# QN908XC register map
Vendor: nxp.com; File version: 1.0
CPU: CM4 r0p1, little endian, no MPU, no FPU, 0x3 interrupt priority bits, 0x0 interrupts
Registers are 32-bit, read-write, reset 0x0 unless marked. A register's access mark holds for its fields unless they carry their own. Offsets are from the block's base; [hi:lo] are bit positions.

## CALIB
Base 0x4000F000
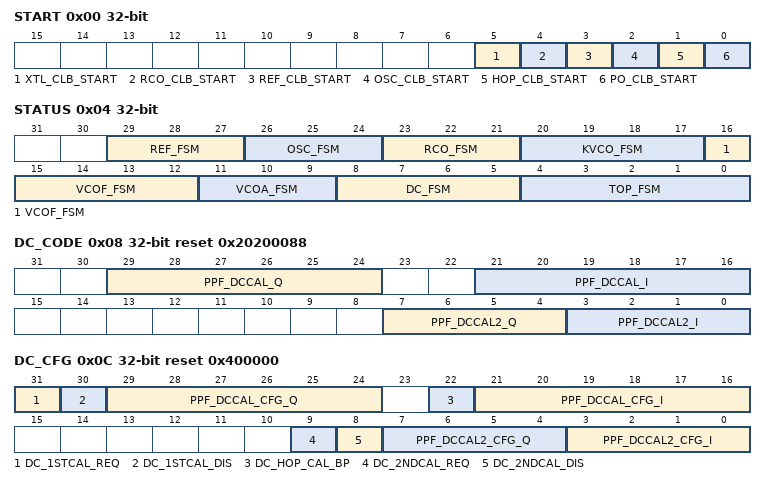
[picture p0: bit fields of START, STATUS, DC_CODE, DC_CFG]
0x00 START reset not defined — calibration start register
  [5] XTL_CLB_START wo — XTAL calibration start
  [4] RCO_CLB_START wo — RCO calibration start
  [3] REF_CLB_START wo — REF PLL calibration start
  [2] OSC_CLB_START wo — OSC calibration start
  [1] HOP_CLB_START wo — Frequency hop calibration start
  [0] PO_CLB_START wo — Power on calibration start
0x04 STATUS ro — calibration FSM status register
  [29:27] REF_FSM, [26:24] OSC_FSM, [23:21] RCO_FSM, [20:17] KVCO_FSM, [16:12] VCOF_FSM, [11:9] VCOA_FSM, [8:5] DC_FSM, [4:0] TOP_FSM
0x08 DC_CODE ro reset 0x20200088 — DC code status register
  [29:24] PPF_DCCAL_Q — DC re-calibration q code
  [21:16] PPF_DCCAL_I — DC re-calibration i code
  [7:4] PPF_DCCAL2_Q — Power on DC calibration q code
  [3:0] PPF_DCCAL2_I — Power on DC calibration i code
0x0C DC_CFG reset 0x400000 — DC code configured code register
  [31] DC_1STCAL_REQ — DC hop calibration request
  [30] DC_1STCAL_DIS — DC hop calibration disable
  [29:24] PPF_DCCAL_CFG_Q — DC re-calibration q code configured
  [22] DC_HOP_CAL_BP — DC hop calibration bypass
  [21:16] PPF_DCCAL_CFG_I — DC re-calibration i code configured
  [9] DC_2NDCAL_REQ — DC calibration request
  [8] DC_2NDCAL_DIS — DC calibration disable
  [7:4] PPF_DCCAL2_CFG_Q — Power on DC calibration q code configured
  [3:0] PPF_DCCAL2_CFG_I — Power on DC calibration i code configured
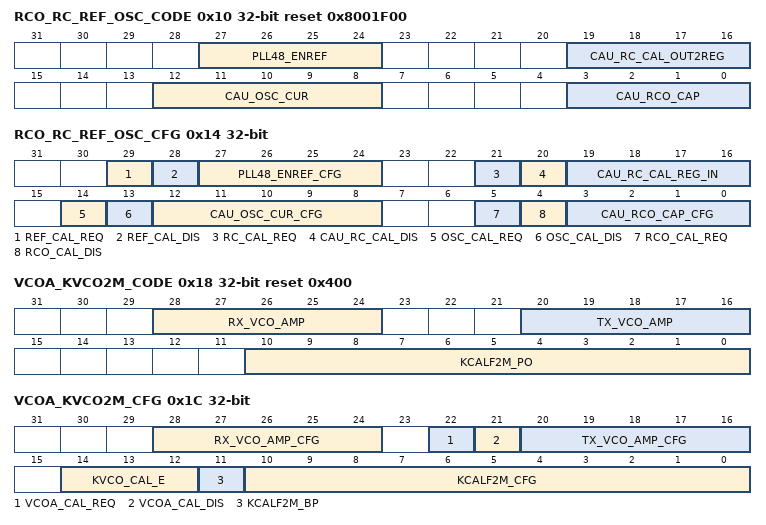
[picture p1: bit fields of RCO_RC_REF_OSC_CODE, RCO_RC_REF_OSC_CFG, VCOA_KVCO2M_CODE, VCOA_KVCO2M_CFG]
0x10 RCO_RC_REF_OSC_CODE ro reset 0x8001F00 — RCO RC PLL48M OSC code status register
  [27:24] PLL48_ENREF — REF calibration output code
  [19:16] CAU_RC_CAL_OUT2REG — RC calibration output code
  [12:8] CAU_OSC_CUR — OSC calibration output code
  [3:0] CAU_RCO_CAP — RCO calibration output code
0x14 RCO_RC_REF_OSC_CFG — RCO RC PLL48M OSC configured code register
  [29] REF_CAL_REQ — REF PLL calibration request
  [28] REF_CAL_DIS — REF PLL calibration disable
  [27:24] PLL48_ENREF_CFG — REF calibration output code configured
  [21] RC_CAL_REQ — RC calibration request
  [20] CAU_RC_CAL_DIS — RC calibration disable
  [19:16] CAU_RC_CAL_REG_IN — RC calibration code to analog
  [14] OSC_CAL_REQ — OSC calibration request
  [13] OSC_CAL_DIS — OSC calibration disable
  [12:8] CAU_OSC_CUR_CFG — OSC calibration output code configured
  [5] RCO_CAL_REQ — RCO calibration request
  [4] RCO_CAL_DIS — RCO calibration disable
  [3:0] CAU_RCO_CAP_CFG — RCO calibration code configured
0x18 VCOA_KVCO2M_CODE ro reset 0x400 — reserved
  [28:24] RX_VCO_AMP — VCO RX amplitude calibration output code
  [20:16] TX_VCO_AMP — VCO TX amplitude calibration output code
  [10:0] KCALF2M_PO — KVCO 2M mode calibration power on code
0x1C VCOA_KVCO2M_CFG — reserved
  [28:24] RX_VCO_AMP_CFG — RX VCO amplitude calibration output code configured
  [22] VCOA_CAL_REQ — VCO amplitude calibration request
  [21] VCOA_CAL_DIS — VCO amplitude calibration disable
  [20:16] TX_VCO_AMP_CFG — TX VCO amplitude calibration output code configured
  [14:12] KVCO_CAL_E
  [11] KCALF2M_BP — bypass KVCO 2M mode power on calibration
  [10:0] KCALF2M_CFG — KVCO 2M mode calibration code configure
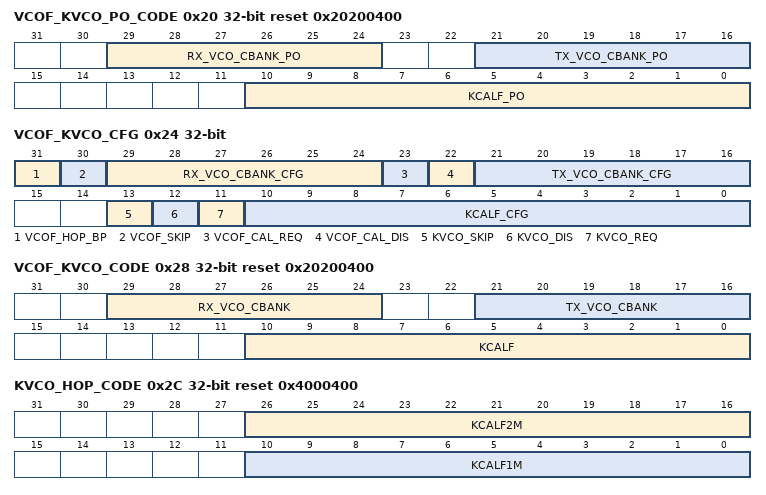
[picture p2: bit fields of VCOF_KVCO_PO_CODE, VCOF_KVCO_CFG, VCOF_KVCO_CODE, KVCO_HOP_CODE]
0x20 VCOF_KVCO_PO_CODE ro reset 0x20200400 — reserved
  [29:24] RX_VCO_CBANK_PO — RX VCO frequency power on calibration output code
  [21:16] TX_VCO_CBANK_PO — TX VCO frequency power on calibration output code
  [10:0] KCALF_PO — KVCO power up calibration result
0x24 VCOF_KVCO_CFG — VCOF hop calibration bypass
  [31] VCOF_HOP_BP — VCOF hop calibration bypass
  [30] VCOF_SKIP — VCOF hop calibration calculation skip
  [29:24] RX_VCO_CBANK_CFG — RX VCO frequency calibration output code configured
  [23] VCOF_CAL_REQ — VCO frequency calibration request
  [22] VCOF_CAL_DIS — VCO frequency calibration disable
  [21:16] TX_VCO_CBANK_CFG — TX VCO frequency calibration output code configured
  [13] KVCO_SKIP — KVCO hop calibration calculation skip
  [12] KVCO_DIS — KVCO calibration disable
  [11] KVCO_REQ — KVCO calibration request
  [10:0] KCALF_CFG — KVCO calibration code configure
0x28 VCOF_KVCO_CODE ro reset 0x20200400 — reserved
  [29:24] RX_VCO_CBANK — RX VCO frequency calibration output code
  [21:16] TX_VCO_CBANK — TX VCO frequency calibration output code
  [10:0] KCALF — KVCO calibration output at carrier frequency
0x2C KVCO_HOP_CODE ro reset 0x4000400 — reserved
  [26:16] KCALF2M — KVCO hop calibration output at carrier frequency in 2M mode
  [10:0] KCALF1M — KVCO hop calibration output at carrier frequency in 1M mode
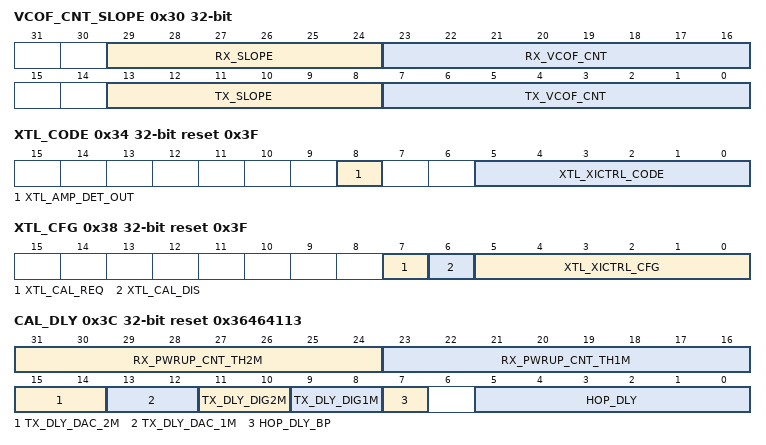
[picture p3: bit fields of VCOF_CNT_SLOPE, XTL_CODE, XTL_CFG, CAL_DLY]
0x30 VCOF_CNT_SLOPE (reset mask 0x1F3F1F3F) — reserved
  [29:24] RX_SLOPE — RX frequency curve slope
  [23:16] RX_VCOF_CNT — RX VCO frequency power up calibration 8us count value
  [13:8] TX_SLOPE — TX frequency curve slope
  [7:0] TX_VCOF_CNT — TX VCO frequency power up calibration 8us count value
0x34 XTL_CODE ro reset 0x3F — Reserved
  [8] XTL_AMP_DET_OUT — crystal comparator output result
  [5:0] XTL_XICTRL_CODE — crystal calibration code
0x38 XTL_CFG reset 0x3F — Reserved
  [7] XTL_CAL_REQ — crystal calibration request
  [6] XTL_CAL_DIS — crystal code disable
  [5:0] XTL_XICTRL_CFG — crystal calibration CFG
0x3C CAL_DLY reset 0x36464113 — hop calibration delay bypass
  [31:24] RX_PWRUP_CNT_TH2M
  [23:16] RX_PWRUP_CNT_TH1M
  [15:14] TX_DLY_DAC_2M
  [13:12] TX_DLY_DAC_1M
  [11:10] TX_DLY_DIG2M
  [9:8] TX_DLY_DIG1M
  [7] HOP_DLY_BP — hop calibration delay bypass
  [5:0] HOP_DLY — hop calibration delay time
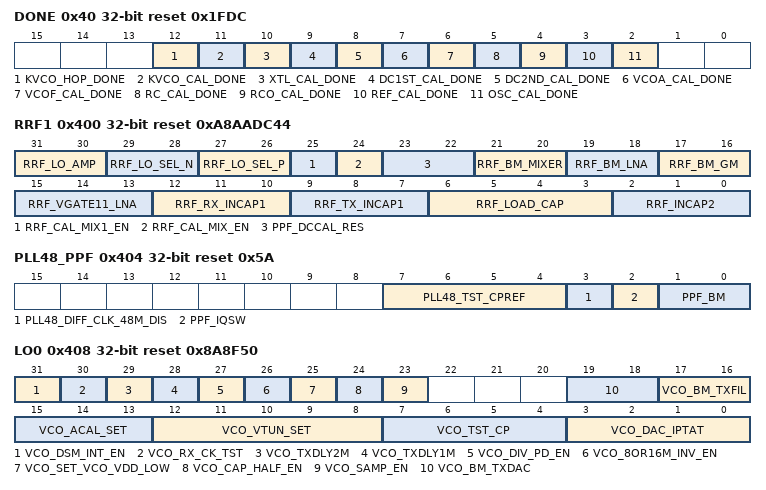
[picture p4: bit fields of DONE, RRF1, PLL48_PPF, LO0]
0x40 DONE ro reset 0x1FDC — Reserved
  [12] KVCO_HOP_DONE — KVCO calibration done
  [11] KVCO_CAL_DONE — KVCO calibration done
  [10] XTL_CAL_DONE — XTL calibration done
  [9] DC1ST_CAL_DONE — DC 1st stage calibration done
  [8] DC2ND_CAL_DONE — DC 2nd stage calibration done
  [7] VCOA_CAL_DONE — VCO amplitude calibration done
  [6] VCOF_CAL_DONE — VCO frequency calibration done
  [5] RC_CAL_DONE — RC calibration done
  [4] RCO_CAL_DONE — RCO calibration done
  [3] REF_CAL_DONE — REF PLL calibration done
  [2] OSC_CAL_DONE — OSC calibration done
0x400 RRF1 reset 0xA8AADC44 — Amplitude of LO buffer for active mixer
  [31:30] RRF_LO_AMP — Amplitude of LO buffer for active mixer
  [29:28] RRF_LO_SEL_N — Dc voltage bias control for the nmos switch of active mixer
  [27:26] RRF_LO_SEL_P — Dc voltage bias control for the pmos switch of active mixer
  [25] RRF_CAL_MIX1_EN
  [24] RRF_CAL_MIX_EN
  [23:22] PPF_DCCAL_RES — Input res selection of ppf for dccal
  [21:20] RRF_BM_MIXER — Mixer current bias
  [19:18] RRF_BM_LNA — LNA bias current control-
  [17:16] RRF_BM_GM — Constant gm current control
  [15:13] RRF_VGATE11_LNA — LNA vrega voltage
  [12:10] RRF_RX_INCAP1 — LNA&PA matching cap bank
  [9:7] RRF_TX_INCAP1 — LNA&PA matching cap bank
  [6:3] RRF_LOAD_CAP — LNA load LC cap bank
  [2:0] RRF_INCAP2 — LNA input LC cap bank
0x404 PLL48_PPF reset 0x5A — reserved
  [7:4] PLL48_TST_CPREF — CP current selecting
  [3] PLL48_DIFF_CLK_48M_DIS
  [2] PPF_IQSW
  [1:0] PPF_BM — Ppf current control-
0x408 LO0 reset 0x8A8F50 — reserved
  [31] VCO_DSM_INT_EN
  [30] VCO_RX_CK_TST
  [29] VCO_TXDLY2M
  [28] VCO_TXDLY1M
  [27] VCO_DIV_PD_EN
  [26] VCO_8OR16M_INV_EN
  [25] VCO_SET_VCO_VDD_LOW
  [24] VCO_CAP_HALF_EN
  [23] VCO_SAMP_EN
  [19:18] VCO_BM_TXDAC — Set the bias current of the TX DAC
  [17:16] VCO_BM_TXFIL — Set the bias current of the TX filter
  [15:13] VCO_ACAL_SET — Set the threshold (differential peak) in VCO amplitude calibration-VTH=0.2+0.05*ACAL_SET
  [12:8] VCO_VTUN_SET — Set VTUNE voltage change in order to properly compensate the VUNE error introduced by charge injection when the PLL loop is broken;VTUNE change introduced by this register is around 50uV*(VTUNE_SET-16)
  [7:4] VCO_TST_CP — LO CP current control-
  [3:0] VCO_DAC_IPTAT — Set the temperature characteristic of TX DAC in order to compensate the modulation gain error of the VCO
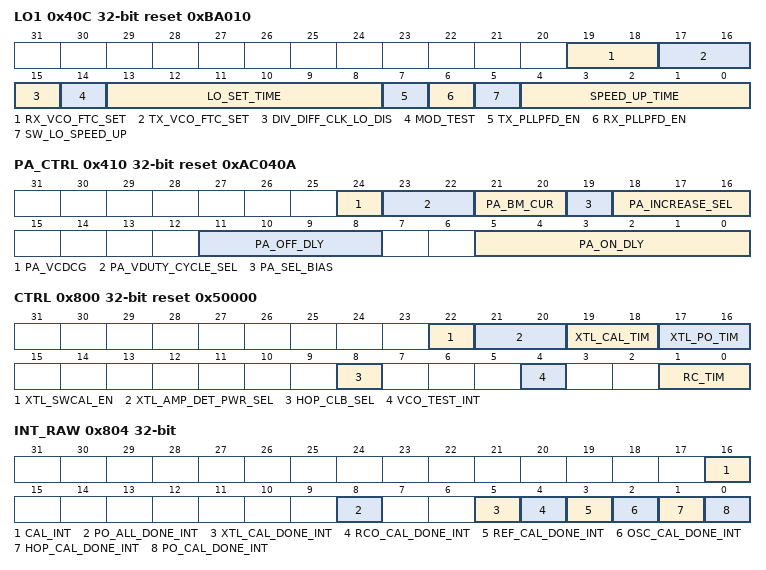
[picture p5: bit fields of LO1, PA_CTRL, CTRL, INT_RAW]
0x40C LO1 reset 0xBA010 — Reserved
  [19:18] RX_VCO_FTC_SET
  [17:16] TX_VCO_FTC_SET
  [15] DIV_DIFF_CLK_LO_DIS
  [14] MOD_TEST — LO open loop or close loop select
  [13:8] LO_SET_TIME — LO settle time
  [7] TX_PLLPFD_EN — PLL pfd enable in TX mode
  [6] RX_PLLPFD_EN — PLL pfd enable in RX mode
  [5] SW_LO_SPEED_UP — software LO speed up
  [4:0] SPEED_UP_TIME — LO speed up time
0x410 PA_CTRL reset 0xAC040A — Reserved
  [24] PA_VCDCG — PA duty cycle control
  [23:22] PA_VDUTY_CYCLE_SEL — PA duty cycle control voltage select
  [21:20] PA_BM_CUR — Pa bias current control
  [19] PA_SEL_BIAS — PA duty cycle voltage bias
  [18:16] PA_INCREASE_SEL — PA output power increasing control
  [11:8] PA_OFF_DLY — PA turn off delay time
  [5:0] PA_ON_DLY — PA turn on delay time
0x800 CTRL reset 0x50000 — Reserved
  [22] XTL_SWCAL_EN — crystal software calibration enable
  [21:20] XTL_AMP_DET_PWR_SEL — crystal amplitude detector power select
    0=PO1MS (power on detector only 1ms each code); 1=POCAL (power on detector during all calibration time); 2=POALWAYS (always power on detector); 3=PDALWAYS (always power down detector)
  [19:18] XTL_CAL_TIM — crystal calibration code wait time
  [17:16] XTL_PO_TIM — crystal calibration power on wait time
  [8] HOP_CLB_SEL — Frequency hop calibration start select
  [4] VCO_TEST_INT
  [1:0] RC_TIM — RC calibration reset time
0x804 INT_RAW — Reserved
  [16] CAL_INT ro — or signal of all calibration interrupt
  [8] PO_ALL_DONE_INT ro — RCO & REF & OSC & Power on calibration all done interrupt. And signal of above interrupt
  [5] XTL_CAL_DONE_INT write-1-clears — XTL calibration done interrupt
  [4] RCO_CAL_DONE_INT write-1-clears — RCO calibration done interrupt
  [3] REF_CAL_DONE_INT write-1-clears — REF PLL calibration done interrupt
  [2] OSC_CAL_DONE_INT write-1-clears — OSC calibration done interrupt
  [1] HOP_CAL_DONE_INT write-1-clears — hop calibration done interrupt
  [0] PO_CAL_DONE_INT write-1-clears — power on calibration done interrupt
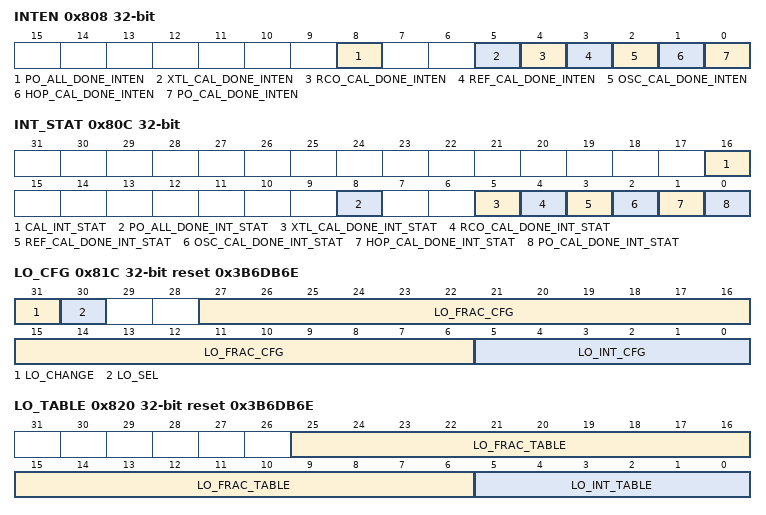
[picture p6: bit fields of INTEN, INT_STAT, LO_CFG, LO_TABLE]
0x808 INTEN — Reserved
  [8] PO_ALL_DONE_INTEN — PO_ALL_DONE_INT enable
  [5] XTL_CAL_DONE_INTEN — XTL calibration done interrupt enable
  [4] RCO_CAL_DONE_INTEN — RCO calibration done interrupt enable
  [3] REF_CAL_DONE_INTEN — REF PLL calibration done interrupt enable
  [2] OSC_CAL_DONE_INTEN — OSC calibration done interrupt enable
  [1] HOP_CAL_DONE_INTEN — hop calibration done interrupt enable
  [0] PO_CAL_DONE_INTEN — power on calibration done interrupt enable
0x80C INT_STAT ro — Reserved
  [16] CAL_INT_STAT — calibration all interrupt status
  [8] PO_ALL_DONE_INT_STAT — PO_ALL_DONE_INT status
  [5] XTL_CAL_DONE_INT_STAT — XTL calibration done interrupt status
  [4] RCO_CAL_DONE_INT_STAT — RCO calibration done interrupt status
  [3] REF_CAL_DONE_INT_STAT — REF PLL calibration done interrupt status
  [2] OSC_CAL_DONE_INT_STAT — OSC calibration done interrupt status
  [1] HOP_CAL_DONE_INT_STAT — hop calibration done interrupt status
  [0] PO_CAL_DONE_INT_STAT — power on calibration done interrupt status
0x810 TIF — reserved
  [3:0] TEST_CTRL — Test interface selection
0x814 KVCO_MEAN ro — reserved
  [20:0] KVCO_CNT_MEAN — KVCO counter 1 and counter 2 mean
0x818 KVCO_DLT ro — reserved
  [8:0] KVCO_CNT_DLT — KVCO counter 1 and counter 2 delta
0x81C LO_CFG reset 0x3B6DB6E
  [31] LO_CHANGE, [30] LO_SEL, [27:6] LO_FRAC_CFG, [5:0] LO_INT_CFG
0x820 LO_TABLE ro reset 0x3B6DB6E
  [25:6] LO_FRAC_TABLE, [5:0] LO_INT_TABLE
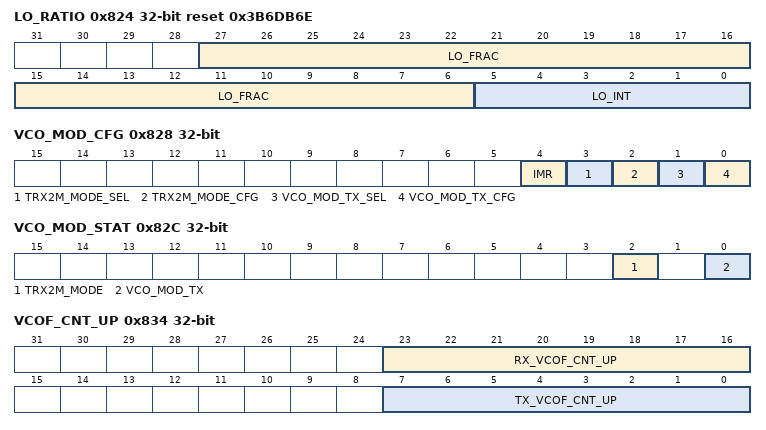
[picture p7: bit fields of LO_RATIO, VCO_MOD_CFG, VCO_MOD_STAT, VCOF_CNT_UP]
0x824 LO_RATIO ro reset 0x3B6DB6E
  [27:6] LO_FRAC, [5:0] LO_INT
0x828 VCO_MOD_CFG — TRX 2M mode selection signal
  [4] IMR
  [3] TRX2M_MODE_SEL — TRX 2M mode selection signal
  [2] TRX2M_MODE_CFG — TRX 2M mode software configured value
  [1] VCO_MOD_TX_SEL — VCO_MOD_TX selection
  [0] VCO_MOD_TX_CFG — VCO_MOD_TX register configured value. See section 6.10.5 for detail.
0x82C VCO_MOD_STAT ro
  [2] TRX2M_MODE, [0] VCO_MOD_TX
0x830 CH_IDX ro reset 0x1
  [7:0] CH_IDX
0x834 VCOF_CNT_UP ro — reserved
  [23:16] RX_VCOF_CNT_UP — RX VCO frequency power up calibration 8us count value
  [7:0] TX_VCOF_CNT_UP — TX VCO frequency power up calibration 8us count value
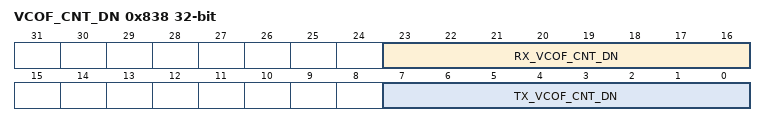
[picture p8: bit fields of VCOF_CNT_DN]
0x838 VCOF_CNT_DN ro — reserved
  [23:16] RX_VCOF_CNT_DN — RX VCO frequency power up calibration 8us count value
  [7:0] TX_VCOF_CNT_DN — TX VCO frequency power up calibration 8us count value
